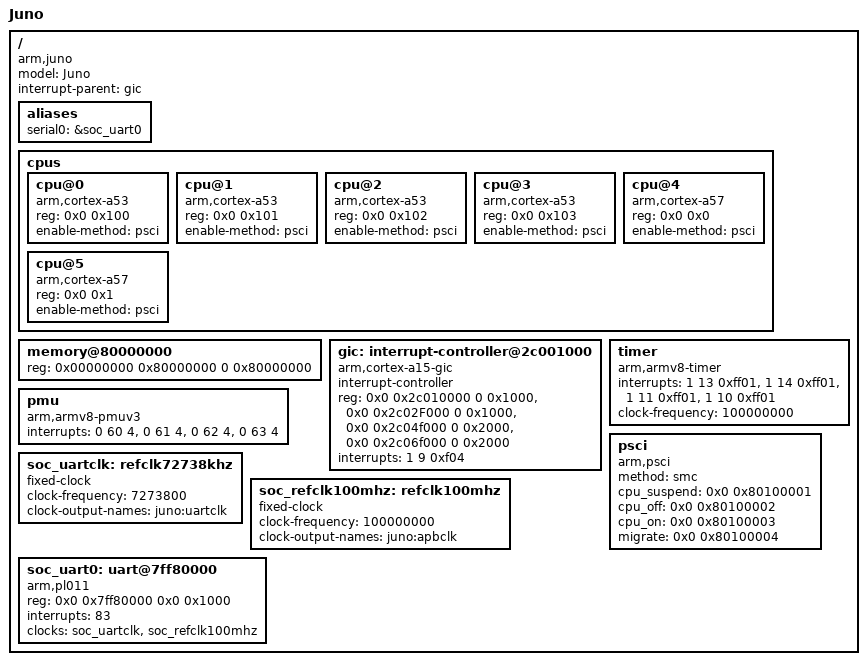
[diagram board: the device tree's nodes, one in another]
/*
 * ARM Ltd. Juno Plaform
 *
 * Fast Models FVP v2 support
 */

/dts-v1/;

/ {
	model = "Juno";
	compatible = "arm,juno", "arm,vexpress";
	interrupt-parent = <&gic>;
	#address-cells = <2>;
	#size-cells = <2>;

	aliases {
		serial0 = &soc_uart0;
	};

	cpus {
		#address-cells = <2>;
		#size-cells = <0>;

		cpu@0 {
			device_type = "cpu";
			compatible = "arm,cortex-a53","arm,armv8";
			reg = <0x0 0x100>;
			enable-method = "psci";
		};
		cpu@1 {
			device_type = "cpu";
			compatible = "arm,cortex-a53","arm,armv8";
			reg = <0x0 0x101>;
			enable-method = "psci";
		};
		cpu@2 {
			device_type = "cpu";
			compatible = "arm,cortex-a53","arm,armv8";
			reg = <0x0 0x102>;
			enable-method = "psci";
		};
		cpu@3 {
			device_type = "cpu";
			compatible = "arm,cortex-a53","arm,armv8";
			reg = <0x0 0x103>;
			enable-method = "psci";
		};
		cpu@4 {
			device_type = "cpu";
			compatible = "arm,cortex-a57","arm,armv8";
			reg = <0x0 0x0>;
			enable-method = "psci";
		};
		cpu@5 {
			device_type = "cpu";
			compatible = "arm,cortex-a57","arm,armv8";
			reg = <0x0 0x1>;
			enable-method = "psci";
		};
	};

	memory@80000000 {
		device_type = "memory";
		reg = <0x00000000 0x80000000 0 0x80000000>;
		/*      <0x00000008 0x80000000 0 0x80000000>; */
	};

	gic: interrupt-controller@2c001000 {
		compatible = "arm,cortex-a15-gic", "arm,cortex-a9-gic";
		#interrupt-cells = <3>;
		#address-cells = <0>;
		interrupt-controller;
		reg = <0x0 0x2c010000 0 0x1000>,
		      <0x0 0x2c02F000 0 0x1000>,
		      <0x0 0x2c04f000 0 0x2000>,
		      <0x0 0x2c06f000 0 0x2000>;
		interrupts = <1 9 0xf04>;
	};

	timer {
		compatible = "arm,armv8-timer";
		interrupts = <1 13 0xff01>,
			     <1 14 0xff01>,
			     <1 11 0xff01>,
			     <1 10 0xff01>;
		clock-frequency = <100000000>;
	};

	pmu {
		compatible = "arm,armv8-pmuv3";
		interrupts = <0 60 4>,
			     <0 61 4>,
			     <0 62 4>,
			     <0 63 4>;
	};

	psci {
		compatible = "arm,psci";
		method = "smc";
		cpu_suspend = <0x0 0x80100001>;
		cpu_off = <0x0 0x80100002>;
		cpu_on = <0x0 0x80100003>;
		migrate = <0x0 0x80100004>;
	};

	/include/ "juno-clocks.dtsi"

	soc_uartclk: refclk72738khz {
		compatible = "fixed-clock";
		#clock-cells = <0>;
		clock-frequency = <7273800>;
		clock-output-names = "juno:uartclk";
	};

	soc_refclk100mhz: refclk100mhz {
		compatible = "fixed-clock";
		#clock-cells = <0>;
		clock-frequency = <100000000>;
		clock-output-names = "juno:apbclk";
	};

	soc_uart0: uart@7ff80000 {
		compatible = "arm,pl011", "arm,primecell";
		reg = <0x0 0x7ff80000 0x0 0x1000>;
		interrupts = <83>;
		clocks = <&soc_uartclk>, <&soc_refclk100mhz>;
		clock-names = "uartclk", "apb_pclk";
	};

	/* soc_uart1: uart@7ff70000 {
		compatible = "arm,pl011", "arm,primecell";
		reg = <0x0 0x7ff70000 0x0 0x1000>;
		interrupts = <84>;
		clocks = <&soc_uartclk>, <&soc_refclk100mhz>;
		clock-names = "uartclk", "apb_pclk";
	}; */

/*	smb {
		compatible = "simple-bus";
		#size-cells = <2>;
		ranges = <0 0 0 0x08000000 0x04000000>,
			 <1 0 0 0x14000000 0x04000000>,
			 <2 0 0 0x18000000 0x04000000>,
			 <3 0 0 0x1c000000 0x04000000>,
			 <4 0 0 0x0c000000 0x04000000>,
			 <5 0 0 0x10000000 0x04000000>;

		#interrupt-cells = <1>;
		interrupt-map-mask = <0 0 63>;
		interrupt-map = <0 0  0 &gic 0  0 4>,
				<0 0  1 &gic 0  1 4>,
				<0 0  2 &gic 0  2 4>,
				<0 0  3 &gic 0  3 4>,
				<0 0  4 &gic 0  4 4>,
				<0 0  5 &gic 0  5 4>,
				<0 0  6 &gic 0  6 4>,
				<0 0  7 &gic 0  7 4>,
				<0 0  8 &gic 0  8 4>,
				<0 0  9 &gic 0  9 4>,
				<0 0 10 &gic 0 10 4>,
				<0 0 11 &gic 0 11 4>,
				<0 0 12 &gic 0 12 4>,
				<0 0 13 &gic 0 13 4>,
				<0 0 14 &gic 0 14 4>,
				<0 0 15 &gic 0 15 4>,
				<0 0 16 &gic 0 16 4>,
				<0 0 17 &gic 0 17 4>,
				<0 0 18 &gic 0 18 4>,
				<0 0 19 &gic 0 19 4>,
				<0 0 20 &gic 0 20 4>,
				<0 0 21 &gic 0 21 4>,
				<0 0 22 &gic 0 22 4>,
				<0 0 23 &gic 0 23 4>,
				<0 0 24 &gic 0 24 4>,
				<0 0 25 &gic 0 25 4>,
				<0 0 26 &gic 0 26 4>,
				<0 0 27 &gic 0 27 4>,
				<0 0 28 &gic 0 28 4>,
				<0 0 29 &gic 0 29 4>,
				<0 0 30 &gic 0 30 4>,
				<0 0 31 &gic 0 31 4>,
				<0 0 32 &gic 0 32 4>,
				<0 0 33 &gic 0 33 4>,
				<0 0 34 &gic 0 34 4>,
				<0 0 35 &gic 0 35 4>,
				<0 0 36 &gic 0 36 4>,
				<0 0 37 &gic 0 37 4>,
				<0 0 38 &gic 0 38 4>,
				<0 0 39 &gic 0 39 4>,
				<0 0 40 &gic 0 40 4>,
				<0 0 41 &gic 0 41 4>,
				<0 0 42 &gic 0 42 4>;

		/include/ "juno-motherboard-peripherals.dtsi"
	}; */
};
